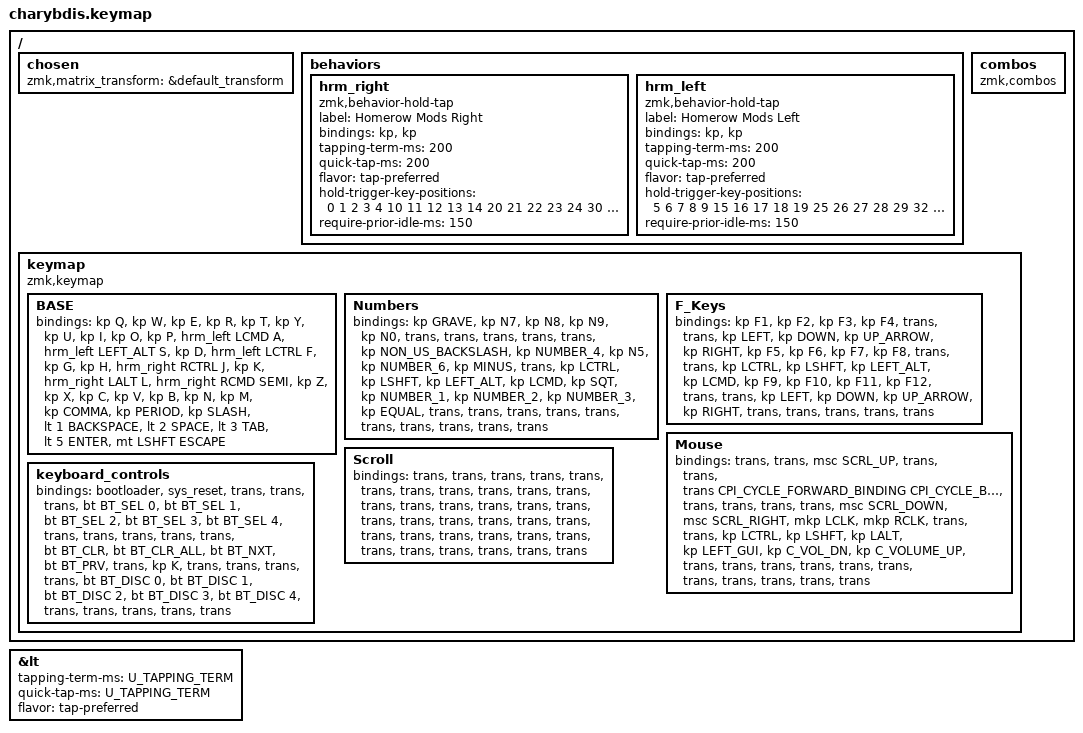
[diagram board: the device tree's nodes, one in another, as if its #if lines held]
#include <behaviors/mouse_keys.dtsi>
#include <dt-bindings/zmk/mouse.h>
#include <behaviors.dtsi>
#include <dt-bindings/zmk/bt.h>
#include <dt-bindings/zmk/keys.h>
#include <dt-bindings/zmk/pointing.h>

#define U_TAPPING_TERM 150

#if defined(CONFIG_SHIELD_CHARYBDIS_RIGHT)

#define CPI_CYCLE_FORWARD_BINDING &cpi_cycle 1
#define CPI_CYCLE_BACKWARD_BINDING &cpi_cycle 3

#else

#define CPI_CYCLE_FORWARD_BINDING &none
#define CPI_CYCLE_BACKWARD_BINDING &none

#endif

&lt {
    tapping-term-ms = < U_TAPPING_TERM >;
    quick-tap-ms = < U_TAPPING_TERM >;
    flavor = "tap-preferred";
};

/ {
    chosen { zmk,matrix_transform = &default_transform; };
};

/ {
    behaviors {
        hrm_right: hrm_right {
            compatible = "zmk,behavior-hold-tap";
            label = "Homerow Mods Right";
            bindings = <&kp>, <&kp>;

            #binding-cells = <2>;
            tapping-term-ms = <200>;
            quick-tap-ms = <200>;
            flavor = "tap-preferred";
            hold-trigger-key-positions = <0 1 2 3 4 10 11 12 13 14 20 21 22 23 24 30 31>;
            require-prior-idle-ms = <150>;
        };

        hrm_left: hrm_left {
            compatible = "zmk,behavior-hold-tap";
            label = "Homerow Mods Left";
            bindings = <&kp>, <&kp>;

            #binding-cells = <2>;
            tapping-term-ms = <200>;
            quick-tap-ms = <200>;
            flavor = "tap-preferred";
            hold-trigger-key-positions = <5 6 7 8 9 15 16 17 18 19 25 26 27 28 29 32 33>;
            require-prior-idle-ms = <150>;
        };
    };

    combos { compatible = "zmk,combos"; };

    keymap {
        compatible = "zmk,keymap";

        BASE {
            bindings = <
&kp Q             &kp W                 &kp E  &kp R              &kp T                   &kp Y  &kp U               &kp I             &kp O              &kp P
&hrm_left LCMD A  &hrm_left LEFT_ALT S  &kp D  &hrm_left LCTRL F  &kp G                   &kp H  &hrm_right RCTRL J  &kp K             &hrm_right LALT L  &hrm_right RCMD SEMI
&kp Z             &kp X                 &kp C  &kp V              &kp B                   &kp N  &kp M               &kp COMMA         &kp PERIOD         &kp SLASH
                                               &lt 1 BACKSPACE    &lt 2 SPACE  &lt 3 TAB         &lt 5 ENTER         &mt LSHFT ESCAPE
            >;
        };

        Numbers {
            bindings = <
&kp GRAVE             &kp N7        &kp N8        &kp N9        &kp N0             &trans  &trans     &trans     &trans        &trans
&kp NON_US_BACKSLASH  &kp NUMBER_4  &kp N5        &kp NUMBER_6  &kp MINUS          &trans  &kp LCTRL  &kp LSHFT  &kp LEFT_ALT  &kp LCMD
&kp SQT               &kp NUMBER_1  &kp NUMBER_2  &kp NUMBER_3  &kp EQUAL          &trans  &trans     &trans     &trans        &trans
                                                  &trans        &trans     &trans          &trans     &trans
            >;
        };

        F_Keys {
            bindings = <
&kp F1  &kp F2   &kp F3   &kp F4   &trans          &trans  &kp LEFT   &kp DOWN   &kp UP_ARROW  &kp RIGHT
&kp F5  &kp F6   &kp F7   &kp F8   &trans          &trans  &kp LCTRL  &kp LSHFT  &kp LEFT_ALT  &kp LCMD
&kp F9  &kp F10  &kp F11  &kp F12  &trans          &trans  &kp LEFT   &kp DOWN   &kp UP_ARROW  &kp RIGHT
                          &trans   &trans  &trans          &trans     &trans
            >;
        };

        Mouse {
            bindings = <
&trans          &trans           &msc SCRL_UP  &trans     &trans          &trans CPI_CYCLE_FORWARD_BINDING CPI_CYCLE_BACKWARD_BINDING  &trans     &trans     &trans    &trans
&msc SCRL_DOWN  &msc SCRL_RIGHT  &mkp LCLK     &mkp RCLK  &trans          &trans                                                       &kp LCTRL  &kp LSHFT  &kp LALT  &kp LEFT_GUI
&kp C_VOL_DN    &kp C_VOLUME_UP  &trans        &trans     &trans          &trans                                                       &trans     &trans     &trans    &trans
                                               &trans     &trans  &trans
            >;
        };

        Scroll {
            bindings = <
&trans  &trans  &trans  &trans  &trans          &trans  &trans  &trans  &trans  &trans
&trans  &trans  &trans  &trans  &trans          &trans  &trans  &trans  &trans  &trans
&trans  &trans  &trans  &trans  &trans          &trans  &trans  &trans  &trans  &trans
                        &trans  &trans  &trans          &trans  &trans
            >;
        };

        keyboard_controls {
            bindings = <
&bootloader  &sys_reset  &trans  &trans  &trans          &bt BT_SEL 0   &bt BT_SEL 1    &bt BT_SEL 2   &bt BT_SEL 3   &bt BT_SEL 4
&trans       &trans      &trans  &trans  &trans          &bt BT_CLR     &bt BT_CLR_ALL  &bt BT_NXT     &bt BT_PRV     &trans
&kp K        &trans      &trans  &trans  &trans          &bt BT_DISC 0  &bt BT_DISC 1   &bt BT_DISC 2  &bt BT_DISC 3  &bt BT_DISC 4
                                 &trans  &trans  &trans                 &trans          &trans
            >;
        };
    };
};
